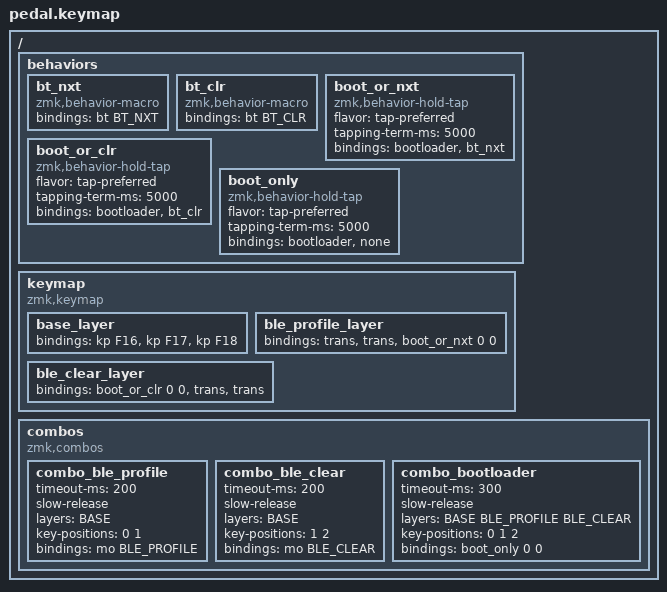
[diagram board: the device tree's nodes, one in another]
#include <behaviors.dtsi>
#include <dt-bindings/zmk/bt.h>
#include <dt-bindings/zmk/keys.h>

#define BASE 0
#define BLE_PROFILE 1
#define BLE_CLEAR 2

/*
 * Switch positions (ordered left to right):
 *   Key 0 = Left pedal   (P0.31)
 *   Key 1 = Center pedal (P0.29)
 *   Key 2 = Right pedal  (P0.02)
 *
 * Chords & functions:
 *   1. Hold two left pedals (0 and 1) -> tap right pedal (2): change BT profile
 *   2. Hold two right pedals (1 and 2) -> tap left pedal (0): clear current BT profile
 *   3. Hold all three pedals down for 5 seconds: enter UF2 bootloader mode
 */

/ {
    behaviors {
        /* Macros wrapping BT commands (0-parameter behaviors for clean hold-tap integration) */
        bt_nxt: bt_nxt {
            compatible = "zmk,behavior-macro";
            #binding-cells = <0>;
            bindings = <&bt BT_NXT>;
        };

        bt_clr: bt_clr {
            compatible = "zmk,behavior-macro";
            #binding-cells = <0>;
            bindings = <&bt BT_CLR>;
        };

        /*
         * Tap: next BT profile.
         * Hold 5 s (when all pedals are down): enter bootloader.
         */
        boot_or_nxt: boot_or_nxt {
            compatible = "zmk,behavior-hold-tap";
            #binding-cells = <2>;
            flavor = "tap-preferred";
            tapping-term-ms = <5000>;
            bindings = <&bootloader>, <&bt_nxt>;
        };

        /*
         * Tap: clear current BT profile.
         * Hold 5 s (when all pedals are down): enter bootloader.
         */
        boot_or_clr: boot_or_clr {
            compatible = "zmk,behavior-hold-tap";
            #binding-cells = <2>;
            flavor = "tap-preferred";
            tapping-term-ms = <5000>;
            bindings = <&bootloader>, <&bt_clr>;
        };

        /* Hold 5 s for bootloader, tap does nothing */
        boot_only: boot_only {
            compatible = "zmk,behavior-hold-tap";
            #binding-cells = <2>;
            flavor = "tap-preferred";
            tapping-term-ms = <5000>;
            bindings = <&bootloader>, <&none>;
        };
    };

    keymap {
        compatible = "zmk,keymap";

        base_layer {
            bindings = <
                &kp F16  &kp F17  &kp F18
            >;
        };

        /* Activated when holding the two left pedals (0 and 1) */
        ble_profile_layer {
            bindings = <
                &trans   &trans   &boot_or_nxt 0 0
            >;
        };

        /* Activated when holding the two right pedals (1 and 2) */
        ble_clear_layer {
            bindings = <
                &boot_or_clr 0 0   &trans   &trans
            >;
        };
    };

    combos {
        compatible = "zmk,combos";

        /* Hold two left pedals -> activate profile selection layer */
        combo_ble_profile {
            timeout-ms = <200>;
            slow-release;
            layers = <BASE>;
            key-positions = <0 1>;
            bindings = <&mo BLE_PROFILE>;
        };

        /* Hold two right pedals -> activate clear profile layer */
        combo_ble_clear {
            timeout-ms = <200>;
            slow-release;
            layers = <BASE>;
            key-positions = <1 2>;
            bindings = <&mo BLE_CLEAR>;
        };

        /* All three pedals held together -> bootloader after 5 seconds */
        combo_bootloader {
            timeout-ms = <300>;
            slow-release;
            layers = <BASE BLE_PROFILE BLE_CLEAR>;
            key-positions = <0 1 2>;
            bindings = <&boot_only 0 0>;
        };
    };
};
